# S32K344 register map
Vendor: NXP Semiconductors; File version: 1.9
CPU: CM7 r0p1, little endian, MPU, FPU, VTOR, 4 interrupt priority bits
Registers are 32-bit, read-write, reset 0x0 unless marked. A register's access mark holds for its fields unless they carry their own. Offsets are from the block's base; [hi:lo] are bit positions; {n}, {i} and the like mark numbered series; 'fields as' and 'values as' point back to an identical list.

## DCM_GPR
Base 0x402AC000; alternate view of DCM
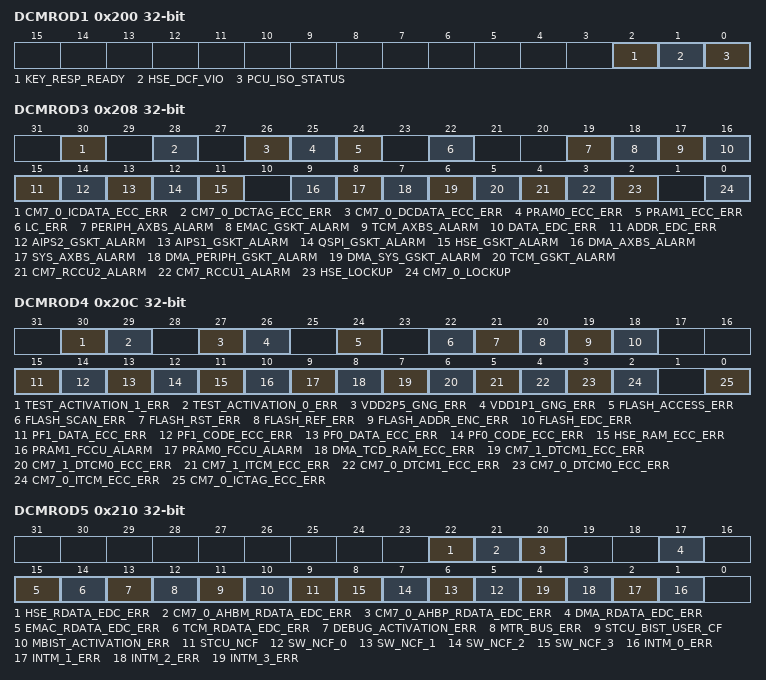
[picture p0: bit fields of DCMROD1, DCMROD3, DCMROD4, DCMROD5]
0x200 DCMROD1 write-1-clears — Read Only GPR On Destructive Reset Register
  [2] KEY_RESP_READY write-1-clears — Key Response Ready
    0=Key response is not ready; 1=Key response is ready
  [1] HSE_DCF_VIO write-1-clears — DCF violation from HSE
    0=No violation from HSE DCF records while decoding; 1=Violation from HSE DCF records while decoding
  [0] PCU_ISO_STATUS write-1-clears — PCU Input Isolation status on previous standby entry
    0=Input isolation did not get enabled in the previous standby entry; 1=Input isolation enabled in the previous standby entry
0x208 DCMROD3 write-1-clears — Read Only GPR On Destructive Reset Register
  [30] CM7_0_ICDATA_ECC_ERR write-1-clears — Multi bit ECC error from CM7_0 ICache data memory
    0=CM7_1 core not in lockup state; 1=CM7_1 core in lockup state
  [28] CM7_0_DCTAG_ECC_ERR write-1-clears — Multi bit ECC error from CM7_0 DCache tag memory. Read this bit to identify the reason of fault in case of FCCU NCF 2.
    0=No multi-bit ECC error; 1=Multi-bit ECC error
  [26] CM7_0_DCDATA_ECC_ERR write-1-clears — Multi bit ECC error from CM7_0 DCache data memory
    0=No multi-bit ECC error; 1=Multi-bit ECC error
  [25] PRAM0_ECC_ERR write-1-clears — Multi bit ECC error from SRAM0
    0=No multi-bit ECC error; 1=Multi-bit ECC error
  [24] PRAM1_ECC_ERR write-1-clears — Multi bit ECC error from SRAM1
    0=No multi-bit ECC error; 1=Multi-bit ECC error
  [22] LC_ERR write-1-clears — Error in Lifecycle Scanning. Read this bit to identify the reason of fault in case of FCCU NCF 3.
    0=No error while lifecycle scanning; 1=Error while lifecycle scanning
  [19] PERIPH_AXBS_ALARM write-1-clears — PERIPH AXBS_Lite Safety Alarm Status. Read this bit to identify the reason of fault in case of FCCU NCF 1.
    0=No safety alarm indicated by Periph AXBS_Lite; 1=Safety alarm indicated by Periph AXBS_Lite
  [18] EMAC_GSKT_ALARM write-1-clears — EMAC IAHB Gasket Alarm Status. Read this bit to identify the reason of fault in case of FCCU NCF 1.
    0=No alarm indicated by EMAC IAHB gasket; 1=Alarm indicated by EMAC IAHB gasket
  [17] TCM_AXBS_ALARM write-1-clears — TCM AHB Splitter Safety Alarm Status. Read this bit to identify the reason of fault in case of FCCU NCF 1.
    0=No safety alarm indicated by TCM AHB splitter; 1=Safety alarm indicated by TCM AHB splitter
  [16] DATA_EDC_ERR write-1-clears — Status of integrity error on data for safety
    0=No integrity error on data; 1=Data integrity error
  [15] ADDR_EDC_ERR write-1-clears — Status of integrity error on address for safety
    0=No integrity error on address; 1=Address integrity error
  [14] AIPS2_GSKT_ALARM write-1-clears — AIPS2 IAHB Gasket Alarm Status. Read this bit to identify the reason of fault in case of FCCU NCF 1.
    0=No alarm indicated by AIPS2 IAHB gasket; 1=Alarm indicated by AIPS2 IAHB gasket
  [13] AIPS1_GSKT_ALARM write-1-clears — AIPS1 IAHB Gasket Alarm Status. Read this bit to identify the reason of fault in case of FCCU NCF 1.
    0=No alarm indicated by AIPS1 IAHB gasket; 1=Alarm indicated by AIPS1 IAHB gasket
  [12] QSPI_GSKT_ALARM write-1-clears — QSPI IAHB Gasket Alarm Status. Read this bit to identify the reason of fault in case of FCCU NCF 1.
    0=No alarm indicated by QSPI IAHB gasket; 1=Alarm indicated by QSPI IAHB gasket
  [11] HSE_GSKT_ALARM write-1-clears — HSE IAHB Gasket Alarm Status. Read this bit to identify the reason of fault in case of FCCU NCF 1.
    0=No alarm indicated by HSE IAHB gasket; 1=Alarm indicated by HSE IAHB gasket
  [9] DMA_AXBS_ALARM write-1-clears — DMA AXBS_Lite Safety Alarm Status. Read this bit to identify the reason of fault in case of FCCU NCF 1.
    0=No safety alarm indicated by DMA AXBS_Lite; 1=Safety alarm indicated by DMA AXBS_Lite
  [8] SYS_AXBS_ALARM write-1-clears — System AXBS Safety Alarm Status. Read this bit to identify the reason of fault in case of FCCU NCF 1.
    0=No safety alarm indicated by system AXBS; 1=Safety alarm indicated by system AXBS
  [7] DMA_PERIPH_GSKT_ALARM write-1-clears — Status of IAHB gasket safety alarm from DMA periph AXBS IAHB gasket
    0=No safety alarm reported from DMA-periph AXBS IAHB gasket; 1=Safety alarm indicated by DMA-periph AXBS IAHB gasket
  [6] DMA_SYS_GSKT_ALARM write-1-clears — Status of IAHB gasket safety alarm from DMA system AXBS IHAB gasket
    0=No safety alarm reported from DMA-system AXBS IAHB gasket; 1=Safety alarm indicated by DMA-system AXBS IAHB gasket
  [5] TCM_GSKT_ALARM write-1-clears — TCM IAHB Gasket Monitor Alarm Status. Read this bit to identify the reason of fault in case of FCCU NCF 1.
    0=No alarm reported from TCM IAHB gasket; 1=Monitor alarm reported from TCM IAHB gasket
  [4] CM7_RCCU2_ALARM write-1-clears — Cortex M7 Cores Redundant Lockstep Error Status. Read this bit to identify the reason of fault in case of FCCU NCF 0.
    0=No lockstep alarm reported by redundant RCCU; 1=Lockstep alarm reported by redundant RCCU
  [3] CM7_RCCU1_ALARM write-1-clears — Cortex M7 Cores Lockstep Error Status. Read this bit to identify the reason of fault in case of FCCU NCF 0.
    0=No lockstep alarm reported by RCCU; 1=Lockstep alarm reported by RCCU
  [2] HSE_LOCKUP write-1-clears — HSE Core Lockup Status. Read this bit to identify the reason of fault in case of FCCU NCF 0.
    0=HSE core not in lockup state; 1=HSE core in lockup state
  [0] CM7_0_LOCKUP write-1-clears — CM7_0 Core Lockup Status. Read this bit to identify the reason of fault in case of FCCU NCF 0.
    0=CM7_0 core not in lockup state; 1=CM7_0 core in lockup state
0x20C DCMROD4 write-1-clears — Read Only GPR On Destructive Reset Register
  [30] TEST_ACTIVATION_1_ERR write-1-clears — Accidental Partial Test Activation. Read this bit to identify the reason of fault in case of FCCU NCF 5.
    0=No partial test activated accidentally; 1=Partial test activated accidentally
  [29] TEST_ACTIVATION_0_ERR write-1-clears — Accidental Partial Test Activation. Read this bit to identify the reason of fault in case of FCCU NCF 5.
    values as TEST_ACTIVATION_1_ERR
  [27] VDD2P5_GNG_ERR write-1-clears — Go/no-go for VDD_HV_FLA (double bond) going to FXOSC and PLL
    0=Go indication referring to the supply being clean; 1=No-go indication referring to the supply being unclean and a fault in double bond connection or its routing within the chip
  [26] VDD1P1_GNG_ERR write-1-clears — Go/no-go indicator for VDD1PD1 (double bond) supply going to PLL
    values as VDD2P5_GNG_ERR
  [24] FLASH_ACCESS_ERR write-1-clears — Transaction Monitor Mismatch Error From Flash Controller
    0=No transaction monitor mismatch error from flash controller; 1=Transaction monitor mismatch error from flash controller
  [22] FLASH_SCAN_ERR write-1-clears — Error while DCM flash scanning process due to invalid data
    0=No error while DCM flash scanning; 1=Error while DCM flash scanning
  [21] FLASH_RST_ERR write-1-clears — Flash Reset Error Status
    0=No flash reset error indicated; 1=Flash reset error indicated
  [20] FLASH_REF_ERR write-1-clears — Flash reference current loss or read voltage error while prevoius read(s)
    0=No reference current loss or read voltage error while previous reads(s); 1=Reference current loss or read voltage error while previous read(s)
  [19] FLASH_ADDR_ENC_ERR write-1-clears — Flash Address Encode Error
    0=No address encode error in flash; 1=Address enocde error in flash
  [18] FLASH_EDC_ERR write-1-clears — Status of flash ECC correction error through EDC reported by FMU
    0=No EDC after ECC error reported in flash; 1=EDC after ECC error reported in flash
  [15] PF1_DATA_ECC_ERR write-1-clears — Flash1 Data ECC Uncorrectable Error
    0=No uncorrectable error reported in flash controller port 1 data memory by FMU; 1=Uncorrectable error reported in flash controller port 1 data memory by FMU
  [14] PF1_CODE_ECC_ERR write-1-clears — Flash1 Code ECC Uncorrectable Error
    0=No uncorrectable error reported in flash controller port 1 code memory by FMU; 1=Uncorrectable error reported in flash controller port 1 code memory by FMU
  [13] PF0_DATA_ECC_ERR write-1-clears — Flash0 Data ECC Uncorrectable Error
    0=No uncorrectable error reported in flash controller port 0 data memory by FMU; 1=Uncorrectable error reported in flash controller port 0 data memory by FMU
  [12] PF0_CODE_ECC_ERR write-1-clears — Flash0 Code ECC Uncorrectable Error
    0=No uncorrectable error reported in flash controller port 0 code memory by FMU; 1=Uncorrectable error reported in flash controller port 0 code memory by FMU
  [11] HSE_RAM_ECC_ERR write-1-clears — HSE RAM Uncorrectable ECC Status. Read this bit to identify the reason of fault in case of FCCU NCF 2.
    0=No uncorrectable ECC reported by HSE RAM; 1=Uncorrectable ECC reported by HSE RAM
  [10] PRAM1_FCCU_ALARM write-1-clears — Status of PRAM1 safety alarm
    0=No safety alarm indicated by PRAM1; 1=Safety alarm indicated by PRAM1
  [9] PRAM0_FCCU_ALARM write-1-clears — Status of PRAM0 safety alarm
    0=No safety alarm indicated by PRAM0; 1=Safety alarm indicated by PRAM0
  [8] DMA_TCD_RAM_ECC_ERR write-1-clears — Uncorrectable ECC error reported from DMA_TCD memory
    0=No uncorrectable ECC error detected; 1=Uncorrectable ECC error detected
  [7] CM7_1_DTCM1_ECC_ERR write-1-clears — Uncorrectable ECC error reported from CM7_1 Data TCM memory block 1
    values as DMA_TCD_RAM_ECC_ERR
  [6] CM7_1_DTCM0_ECC_ERR write-1-clears — Uncorrectable ECC error reported from CM7_1 Data TCM memory block 0
    values as DMA_TCD_RAM_ECC_ERR
  [5] CM7_1_ITCM_ECC_ERR write-1-clears — Uncorrectable ECC error reported from CM7_1 Instruction TCM memory
    values as DMA_TCD_RAM_ECC_ERR
  [4] CM7_0_DTCM1_ECC_ERR write-1-clears — Uncorrectable ECC error reported from CM7_0 Data TCM memory block 1
    values as DMA_TCD_RAM_ECC_ERR
  [3] CM7_0_DTCM0_ECC_ERR write-1-clears — Uncorrectable ECC error reported from CM7_0 Data TCM memory block 0
    values as DMA_TCD_RAM_ECC_ERR
  [2] CM7_0_ITCM_ECC_ERR write-1-clears — Uncorrectable ECC error reported from CM7_0 Instruction TCM memory
    values as DMA_TCD_RAM_ECC_ERR
  [0] CM7_0_ICTAG_ECC_ERR write-1-clears — Multi bit ECC error from CM7_0 ICache tag memory
    0=No multi-bit ECC error; 1=Multi-bit ECC error
0x210 DCMROD5 write-1-clears — Read Only GPR On Destructive Reset Register
  [22] HSE_RDATA_EDC_ERR write-1-clears — Integrity (EDC) error on HSE read data for safety
    0=No integrity error reported on HSE read data; 1=Integrity error reported on HSE read data
  [21] CM7_0_AHBM_RDATA_EDC_ERR write-1-clears — Integrity error on CM7_0 main read data for safety
    0=No integrity error reported on CM7_0 main read data; 1=Integrity error reported on CM7_0 main read data
  [20] CM7_0_AHBP_RDATA_EDC_ERR write-1-clears — Integrity error on CM7_0 peripheral read data for safety
    0=No integrity error reported on CM7_0 peripheral read data; 1=Integrity error reported on CM7_0 peripheral read data
  [17] DMA_RDATA_EDC_ERR write-1-clears — Integrity(EDC) error on eDMA read data for safety
    0=No integrity error reported on eDMA read data; 1=Integrity error reported on eDMA read data
  [15] EMAC_RDATA_EDC_ERR write-1-clears — Integrity(EDC) error on EMAC read data for safety
    0=No integrity error reported on EMAC read data; 1=Integrity error reported on EMAC read data
  [14] TCM_RDATA_EDC_ERR write-1-clears — Integrity(EDC) error on TCM read data for safety
    0=No integrity error reported on TCM read data; 1=Integrity error reported on TCM read data
  [13] DEBUG_ACTIVATION_ERR write-1-clears — Monitoring of unintended debug activation
    0=Unintended debug not activated; 1=Unintended debug activated
  [12] MTR_BUS_ERR write-1-clears — Fault reported due to illegal access on MTR
    0=No transfer error indicated from MTR; 1=Transfer error indicated from MTR
  [11] STCU_BIST_USER_CF write-1-clears — L/M BIST enabled accidentally
    0=No accidental L/M BIST enabled; 1=Accidental L/M BIST enabled
  [10] MBIST_ACTIVATION_ERR write-1-clears — Indicates an accidental backdoor access on memories
    0=No accidental backdoor enabled on memories; 1=Accidental backdoor enabled on memories
  [9] STCU_NCF write-1-clears — STCU non-critical fault, that is, BIST result error
    0=STCU non-critical fault not reported; 1=STCU non-critical fault reported
  [n+5] SW_NCF_{n} write-1-clears (n=0..3) — Software NCF{n} Status
    0=Software NCF{n}, DCMRWF1[FCCU_SW_NCF{n}] not enabled by software; 1=Software NCF{n}, DCMRWF1[FCCU_SW_NCF{n}] enabled by software
  [n+1] INTM_{n}_ERR write-1-clears (n=0..3) — Interrupt monitor{n} error reported by INTM
    0=No error reported by interrupt monitor {n}; 1=Error reported by interrupt monitor {n}
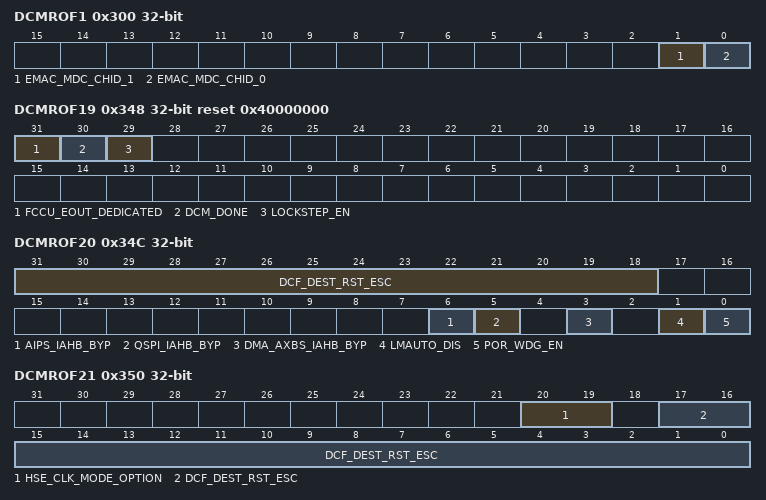
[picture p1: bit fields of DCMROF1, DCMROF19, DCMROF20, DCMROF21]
0x300 DCMROF1 write-1-clears — Read Only GPR On Functional Reset Register
  [1] EMAC_MDC_CHID_1 write-1-clears — EMAC DMA Channel ID1 Status
    0=Channel ID1 is not the current transfer channel ID; 1=Channel ID1 is the current transfer channel ID
  [0] EMAC_MDC_CHID_0 write-1-clears — EMAC DMA Channel ID0 Status
    0=Channel ID0 is not the current transfer channel ID; 1=Channel ID0 is the current transfer channel ID
{0x2FC+4i} DCMROF{i} write-1-clears (i=2..17) — Read Only GPR On Functional Reset Register
  [31:0] DCF_SDID{i-2} write-1-clears — Configuration bits of DCF client SDID {i-2}.
0x348 DCMROF19 ro reset 0x40000000 — Read Only GPR On Functional Reset Register
  [31] FCCU_EOUT_DEDICATED
    0=FCCU_EOUT pins on GPIO2 and GPIO3 acts as general purpose pins supporting all functions; 1=FCCU_EOUT pins on GPIO2 and GPIO3 acts as dedicated EOUT pins
  [30] DCM_DONE
    0=Flash scanning by DCM not complete; 1=Flash scanning completed by DCM
  [29] LOCKSTEP_EN — Lockstep Enable
    0=The chip current operation mode is decoupled operation of CM7_0 and CM7_1; 1=The chip current operation mode is lockstep operation of CM7_0 and CM7_1
0x34C DCMROF20 ro (reset mask 0x3FF94) — Read Only GPR On Functional Reset Register
  [31:18] DCF_DEST_RST_ESC — This register indicates the information of chip destructive reset escalation support for destructive reset sources as configured in DCF record, DEST_RST_ESC[13:0]
    0=Destructive Reset Escalation disabled; 1=Destructive Reset Escalation enabled
  [6] AIPS_IAHB_BYP — Status of AIPS1/2 IAHB gasket as configured in DCF record, UTEST_MISC[AIPS_IAHB_BYP].
    0=Register wall enabled; 1=Register wall bypassed
  [5] QSPI_IAHB_BYP — Status of QSPI IAHB gasket as configured in DCF record, UTEST_MISC[QSPI_IAHB_BYP].
    0=Register wall enabled; 1=Register wall bypassed
  [3] DMA_AXBS_IAHB_BYP — Status of DMA AXBS IAHB gasket as configured in DCF record, UTEST_MISC[DMA_AXBS_IAHB_BYP].
    0=Register wall enabled; 1=Register wall bypassed
  [1] LMAUTO_DIS — PMC last mile automatic croosover from boot regulationfeature support.
    0=Last mile auto crossover feautre is supported for the chip; 1=Last mile auto crossover feautre is not supported for the chip
  [0] POR_WDG_EN — Indicates the status of POR_WDG as configured in DCF record, UTEST_MISC[POR_WDG_EN].
    0=POR Watchdog Disabled; 1=POR Watchdog Enabled (default)
0x350 DCMROF21 ro — Read Only GPR On Functional Reset Register
  [20:19] HSE_CLK_MODE_OPTION — HSE Clock Mode Option
    0=Applicable for clocking option A. Ratio of 1:2 in between HSE IPS interface clock (AIPS_SLOW_CLK) and HSE module clock (HSE_CLK), HSE_IAHB gasket enabled.; 1=Applicable for clocking option C, D, E, E2, and F. Ratio of 1:2 in between HSE IPS interface clock (AIPS_SLOW_CLK) and HSE module clock (HSE_CLK), HSE_IAHB gasket bypass.; 2=10b and 11b both are applicable for clocking option B in same way. Ratio of 1:4 in between HSE IPS interface clock (AIPS_SLOW_CLK) and HSE module clock (HSE_CLK), HSE_IAHB gasket enabled.; 3=10b and 11b both are applicable for clocking option B in same way. Ratio of 1:4 in between HSE IPS interface clock (AIPS_SLOW_CLK) and HSE module clock (HSE_CLK), HSE_IAHB gasket enabled.
  [17:0] DCF_DEST_RST_ESC — This register indicates the information of chip destructive reset escalation support for destructive reset sources as configured in DCF record, DEST_RST_ESC[31:14]
    values as DCMROF20.DCF_DEST_RST_ESC
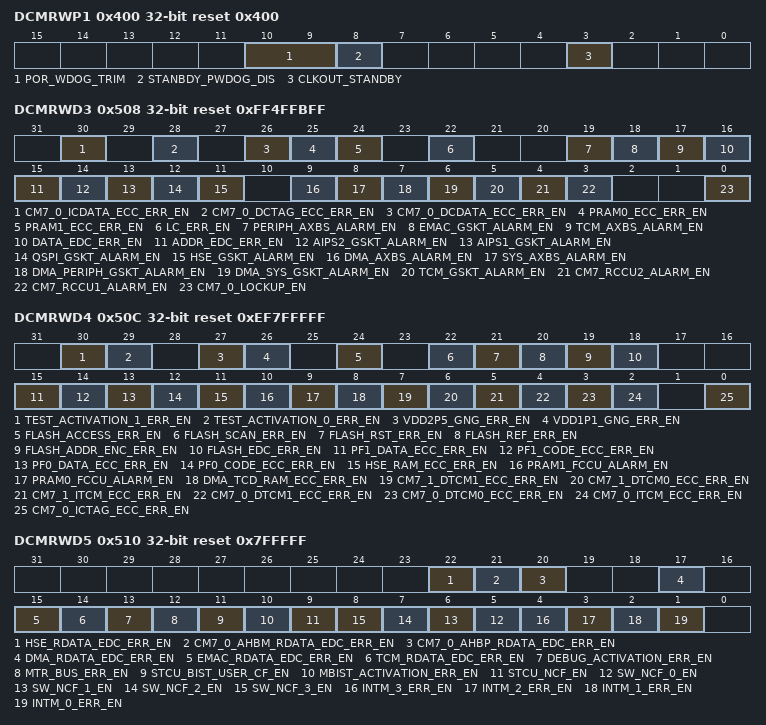
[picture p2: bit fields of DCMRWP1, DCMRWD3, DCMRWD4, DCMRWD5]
0x400 DCMRWP1 reset 0x400 — Read Write GPR On Power On Reset Register
  [10:9] POR_WDOG_TRIM — Trims for POR WDG timeout value.
  [8] STANBDY_PWDOG_DIS — Disables the standby entry and exit monitoring window of the POR WDOG.
    0=Enabled; 1=Disabled
  [3] CLKOUT_STANDBY — Clockout standby expose over functional and destructive reset.
    0=The CLKOUT_STANDBY function is not available while functional or destructive reset on PTA12; 1=The CLKOUT_STANDBY function is available while functional or destructive reset on PTA12
0x408 DCMRWP3 — Read Write GPR On Power On Reset Register
  [9] DEST_RST9_AS_IPI — Configures a destructive reset to interrupt.
    0=Destructive reset; 1=PLL LOL interrupt
0x504 DCMRWD2 — Read Write GPR On Destructive Reset Register
  [7] EOUT_STAT_DUR_STEST — Controls the EOUT state during selftest.
    0=EOUT state will change to high Z post selftest when device is under reset; 1=EOUT state will remain in FAULT state until this bit is cleared
0x508 DCMRWD3 reset 0xFF4FFBFF — Read Write GPR On Destructive Reset Register
  [30] CM7_0_ICDATA_ECC_ERR_EN — Enable bit for enabling the fault monitoring at FCCU NCF 2 for the fault: Multi bit ECC error from CM7_0 ICache data memory
    0=No multi-bit ECC error; 1=Multi-bit ECC error
  [28] CM7_0_DCTAG_ECC_ERR_EN — Enable bit for enabling the fault monitoring at FCCU NCF 2 for the fault: Multi bit ECC error from CM7_0 DCache tag memory
    0=No multi-bit ECC error; 1=Multi-bit ECC error
  [26] CM7_0_DCDATA_ECC_ERR_EN — Enable bit for enabling the fault monitoring at FCCU NCF 2 for the fault: Multi bit ECC error from CM7_0 DCache data memory
    0=No multi-bit ECC error; 1=Multi-bit ECC error
  [25] PRAM0_ECC_ERR_EN — Enable bit for enabling the fault monitoring at FCCU NCF 2 for the fault: Multi bit ECC error from SRAM0
    0=No multi-bit ECC error; 1=Multi-bit ECC error
  [24] PRAM1_ECC_ERR_EN — Enable bit for enabling the fault monitoring at FCCU NCF 2 for the fault: Multi bit ECC error from SRAM1
    0=No multi-bit ECC error; 1=Multi-bit ECC error
  [22] LC_ERR_EN — Enable bit for enabling the fault monitoring at FCCU NCF 3 for the fault: Error in lifecycle scanning
    values as DCMROD3.LC_ERR
  [19] PERIPH_AXBS_ALARM_EN — Enable bit for enabling the fault monitoring at FCCU NCF 1 for the fault: PERIPH AXBS_Lite safety alarm
    values as DCMROD3.PERIPH_AXBS_ALARM
  [18] EMAC_GSKT_ALARM_EN — Enable bit for enabling the fault monitoring at FCCU NCF 1 for the fault: EMAC IAHB gasket alarm.
    values as DCMROD3.EMAC_GSKT_ALARM
  [17] TCM_AXBS_ALARM_EN — Enable bit for enabling the fault monitoring at FCCU NCF 1 for the fault: TCM AHB splitter safety alarm
    values as DCMROD3.TCM_AXBS_ALARM
  [16] DATA_EDC_ERR_EN — Enable bit for enabling the fault monitoring at FCCU NCF 1 for the fault: integrity error on data for safety
    0=No integrity error on data; 1=Data integrity error
  [15] ADDR_EDC_ERR_EN — Enable bit for enabling the fault monitoring at FCCU NCF 1 for the fault: integrity error on address for safety
    0=No integrity error on address; 1=Address integrity error
  [14] AIPS2_GSKT_ALARM_EN — Enable bit for enabling the fault monitoring at FCCU NCF 1 for the fault: AIPS2 IAHB gasket alarm.
    values as DCMROD3.AIPS2_GSKT_ALARM
  [13] AIPS1_GSKT_ALARM_EN — Enable bit for enabling the fault monitoring at FCCU NCF 1 for the fault: AIPS1 IAHB gasket alarm.
    values as DCMROD3.AIPS1_GSKT_ALARM
  [12] QSPI_GSKT_ALARM_EN — Enable bit for enabling the fault monitoring at FCCU NCF 1 for the fault: QSPI IAHB gasket alarm.
    values as DCMROD3.QSPI_GSKT_ALARM
  [11] HSE_GSKT_ALARM_EN — Enable bit for enabling the fault monitoring at FCCU NCF 1 for the fault: HSE IAHB gasket alarm.
    values as DCMROD3.HSE_GSKT_ALARM
  [9] DMA_AXBS_ALARM_EN — Enable bit for enabling the fault monitoring at FCCU NCF 1 for the fault: DMA AXBS_Lite safety alarm
    values as DCMROD3.DMA_AXBS_ALARM
  [8] SYS_AXBS_ALARM_EN — Enable bit for enabling the fault monitoring at FCCU NCF 1 for the fault: system AXBS safety alarm.
    values as DCMROD3.SYS_AXBS_ALARM
  [7] DMA_PERIPH_GSKT_ALARM_EN — Enable bit for enabling the fault monitoring at FCCU NCF 1 for the fault: IAHB gasket safety alarm from DMA periph AXBS IAHB gasket
    values as DCMROD3.DMA_PERIPH_GSKT_ALARM
  [6] DMA_SYS_GSKT_ALARM_EN — Enable bit for enabling the fault monitoring at FCCU NCF 1 for the fault: IAHB gasket safety alarm from DMA system AXBS IHAB gasket
    values as DCMROD3.DMA_SYS_GSKT_ALARM
  [5] TCM_GSKT_ALARM_EN — Enable bit for enabling the fault monitoring at FCCU NCF 1 for the fault: TCM IAHB Gasket monitor alarm
    values as DCMROD3.TCM_GSKT_ALARM
  [4] CM7_RCCU2_ALARM_EN — Enable bit for enabling the fault monitoring at FCCU NCF 0 for the fault: Cortex M7 cores redundant lockstep error
    values as DCMROD3.CM7_RCCU2_ALARM
  [3] CM7_RCCU1_ALARM_EN — Enable bit for enabling the fault monitoring at FCCU NCF 0 for the fault: Cortex M7 cores lockstep error
    values as DCMROD3.CM7_RCCU1_ALARM
  [0] CM7_0_LOCKUP_EN — Enable bit for enabling the fault monitoring at FCCU NCF 0 for the fault: CM7_0 core lockup.
    values as DCMROD3.CM7_0_LOCKUP
0x50C DCMRWD4 reset 0xEF7FFFFF — Read Write GPR On Destructive Reset Register
  [30] TEST_ACTIVATION_1_ERR_EN — Enable bit for enabling the fault monitoring at FCCU NCF 5 for the fault: Accidental partial test activation
    values as DCMROD4.TEST_ACTIVATION_1_ERR
  [29] TEST_ACTIVATION_0_ERR_EN — Enable bit for enabling the fault monitoring at FCCU NCF 5 for the fault: Accidental partial test activation
    values as DCMROD4.TEST_ACTIVATION_1_ERR
  [27] VDD2P5_GNG_ERR_EN — Enable bit for enabling the fault monitoring at FCCU NCF 4 for the fault: Go/Nogo for VDD_HV_FLA (double bond) going to FXOSC and PLL
    0=Go indication referring to the supply being clean; 1=No go indication referring to the supply being unclean and a fault in double bond connection or its routing within the chip
  [26] VDD1P1_GNG_ERR_EN — Enable bit for enabling the fault monitoring at FCCU NCF 4 for the fault: Go/Nogo indicator for VDD1PD1 (double bond) supply going to PLL
    values as VDD2P5_GNG_ERR_EN
  [24] FLASH_ACCESS_ERR_EN — Enable bit for enabling the fault monitoring at FCCU NCF 3 for the fault: Transaction monitor mismatch error from flash controller
    values as DCMROD4.FLASH_ACCESS_ERR
  [22] FLASH_SCAN_ERR_EN — Enable bit for enabling the fault monitoring at FCCU NCF 3 for the fault: Error while DCM flash scanning process due to invalid data
    values as DCMROD4.FLASH_SCAN_ERR
  [21] FLASH_RST_ERR_EN — Enable bit for enabling the fault monitoring at FCCU NCF 3 for the fault: Flash reset error
    values as DCMROD4.FLASH_RST_ERR
  [20] FLASH_REF_ERR_EN — Enable bit for enabling the fault monitoring at FCCU NCF 3 for the fault: Flash reference current loss or read voltage error while prevoius read(s)
    values as DCMROD4.FLASH_REF_ERR
  [19] FLASH_ADDR_ENC_ERR_EN — Enable bit for enabling the fault monitoring at FCCU NCF 3 for the fault: Flash address encode error
    0=No address encode error in flash; 1=Address encode error in flash
  [18] FLASH_EDC_ERR_EN — Enable bit for enabling the fault monitoring at FCCU NCF 3 for the fault: Flash ECC correction error through EDC reported by FMU
    values as DCMROD4.FLASH_EDC_ERR
  [15] PF1_DATA_ECC_ERR_EN — Enable bit for enabling the fault monitoring at FCCU NCF 3 for the fault: Flash1 data ECC uncorrectable error
    values as DCMROD4.PF1_DATA_ECC_ERR
  [14] PF1_CODE_ECC_ERR_EN — Enable bit for enabling the fault monitoring at FCCU NCF 3 for the fault: Flash1 code ECC uncorrectable error
    values as DCMROD4.PF1_CODE_ECC_ERR
  [13] PF0_DATA_ECC_ERR_EN — Enable bit for enabling the fault monitoring at FCCU NCF 3 for the fault: Flash0 data ECC uncorrectable error
    values as DCMROD4.PF0_DATA_ECC_ERR
  [12] PF0_CODE_ECC_ERR_EN — Enable bit for enabling the fault monitoring at FCCU NCF 3 for the fault: Flash0 code ECC uncorrectable error
    values as DCMROD4.PF0_CODE_ECC_ERR
  [11] HSE_RAM_ECC_ERR_EN — Enable bit for enabling the fault monitoring at FCCU NCF 2 for the fault: HSE RAM Uncorrectable ECC
    values as DCMROD4.HSE_RAM_ECC_ERR
  [10] PRAM1_FCCU_ALARM_EN — Enable bit for enabling the fault monitoring at FCCU NCF 2 for the fault: PRAM1 safety alarm
    values as DCMROD4.PRAM1_FCCU_ALARM
  [9] PRAM0_FCCU_ALARM_EN — Enable bit for enabling the fault monitoring at FCCU NCF 2 for the fault: PRAM0 safety alarm
    values as DCMROD4.PRAM0_FCCU_ALARM
  [8] DMA_TCD_RAM_ECC_ERR_EN — Enable bit for enabling the fault monitoring at FCCU NCF 2 for the fault: Uncorrectable ECC error reported from DMA_TCD memory
    0=Uncorrectable ECC error detection at FCCU not enabled; 1=Uncorrectable ECC error detection enabled at FCCU
  [7] CM7_1_DTCM1_ECC_ERR_EN — Enable bit for enabling the fault monitoring at FCCU NCF 2 for the fault: Uncorrectable ECC error from CM7_1 Data TCM memory block 1
    values as DMA_TCD_RAM_ECC_ERR_EN
  [6] CM7_1_DTCM0_ECC_ERR_EN — Enable bit for enabling the fault monitoring at FCCU NCF 2 for the fault: Uncorrectable ECC error from CM7_1 Data TCM memory block 0
    values as DMA_TCD_RAM_ECC_ERR_EN
  [5] CM7_1_ITCM_ECC_ERR_EN — Enable bit for enabling the fault monitoring at FCCU NCF 2 for the fault: Uncorrectable ECC error from CM7_1 Instruction TCM memory
    values as DMA_TCD_RAM_ECC_ERR_EN
  [4] CM7_0_DTCM1_ECC_ERR_EN — Enable bit for enabling the fault monitoring at FCCU NCF 2 for the fault: Uncorrectable ECC error from CM7_0 Data TCM memory block 1
    values as DMA_TCD_RAM_ECC_ERR_EN
  [3] CM7_0_DTCM0_ECC_ERR_EN — Enable bit for enabling the fault monitoring at FCCU NCF 2 for the fault: Uncorrectable ECC error from CM7_0 Data TCM memory block 0
    values as DMA_TCD_RAM_ECC_ERR_EN
  [2] CM7_0_ITCM_ECC_ERR_EN — Enable bit for enabling the fault monitoring at FCCU NCF 2 for the fault: Uncorrectable ECC error from CM7_0 Instruction TCM memory
    values as DMA_TCD_RAM_ECC_ERR_EN
  [0] CM7_0_ICTAG_ECC_ERR_EN — Enable bit for enabling the fault monitoring at FCCU NCF 2 for the fault: Multi bit ECC error from CM7_0 ICache tag memory
    0=No multi-bit ECC error; 1=Multi-bit ECC error
0x510 DCMRWD5 reset 0x7FFFFF — Read Write GPR On Destructive Reset Register
  [22] HSE_RDATA_EDC_ERR_EN — Enable bit for enabling the fault monitoring at FCCU NCF 1 for the fault: Integrity (EDC) error on HSE read data for safety
    values as DCMROD5.HSE_RDATA_EDC_ERR
  [21] CM7_0_AHBM_RDATA_EDC_ERR_EN — Enable bit for enabling the fault monitoring at FCCU NCF 1 for the fault: Integrity error on CM7_0 main read data for safety
    values as DCMROD5.CM7_0_AHBM_RDATA_EDC_ERR
  [20] CM7_0_AHBP_RDATA_EDC_ERR_EN — Enable bit for enabling the fault monitoring at FCCU NCF 1 for the fault: Integrity error on CM7_0 peripheral read data for safety
    values as DCMROD5.CM7_0_AHBP_RDATA_EDC_ERR
  [17] DMA_RDATA_EDC_ERR_EN — Enable bit for enabling the fault monitoring at FCCU NCF 1 for the fault: Integrity(EDC) error on eDMA read data for safety
    values as DCMROD5.DMA_RDATA_EDC_ERR
  [15] EMAC_RDATA_EDC_ERR_EN — Enable bit for enabling the fault monitoring at FCCU NCF 1 for the fault: Integrity(EDC) error on EMAC read data for safety
    values as DCMROD5.EMAC_RDATA_EDC_ERR
  [14] TCM_RDATA_EDC_ERR_EN — Enable bit for enabling the fault monitoring at FCCU NCF 1 for the fault: Integrity(EDC) error on TCM read data for safety
    values as DCMROD5.TCM_RDATA_EDC_ERR
  [13] DEBUG_ACTIVATION_ERR_EN — Enable bit for enabling the fault monitoring at FCCU NCF 5 for the fault: Monitoring of unintended debug activation
    values as DCMROD5.DEBUG_ACTIVATION_ERR
  [12] MTR_BUS_ERR_EN — Enable bit for enabling the fault monitoring at FCCU NCF 5 for the fault: Fault reported due to illegal access on MTR
    values as DCMROD5.MTR_BUS_ERR
  [11] STCU_BIST_USER_CF_EN — Enable bit for enabling the fault monitoring at FCCU NCF 5 for the fault: L/M BIST enabled accidentally
    values as DCMROD5.STCU_BIST_USER_CF
  [10] MBIST_ACTIVATION_ERR_EN — Enable bit for enabling the fault monitoring at FCCU NCF 5 for the fault: Indicates an accidental backdoor access on memories
    values as DCMROD5.MBIST_ACTIVATION_ERR
  [9] STCU_NCF_EN — Enable bit for enabling the fault monitoring at FCCU NCF 5 for the fault: STCU non-critical fault, that is, BIST result error
    values as DCMROD5.STCU_NCF
  [n+5] SW_NCF_{n}_EN (n=0..3) — Enable bit for enabling the fault monitoring at FCCU NCF 7 for the fault: Software NCF{n}
    values as DCMROD5.SW_NCF_0
  [4] INTM_3_ERR_EN — Enable bit for enabling the fault monitoring at FCCU NCF 6 for the fault: Interrupt monitor3 error reported by error reported by INTM
    0=No error reported by interrupt monitor 3; 1=Error reported by interrupt monitor 3
  [3] INTM_2_ERR_EN — Enable bit for enabling the fault monitoring at FCCU NCF 6 for the fault: Interrupt monitor2 error reported by error reported by INTM
    0=No error reported by interrupt monitor 2; 1=Error reported by interrupt monitor 2
  [2] INTM_1_ERR_EN — Enable bit for enabling the fault monitoring at FCCU NCF 6 for the fault: Interrupt monitor1 error reported by error reported by INTM
    0=No error reported by interrupt monitor 1; 1=Error reported by interrupt monitor 1
  [1] INTM_0_ERR_EN — Enable bit for enabling the fault monitoring at FCCU NCF 6 for the fault: Interrupt monitor0 error reported by INTM
    0=No error reported by interrupt monitor 0; 1=Error reported by interrupt monitor 0
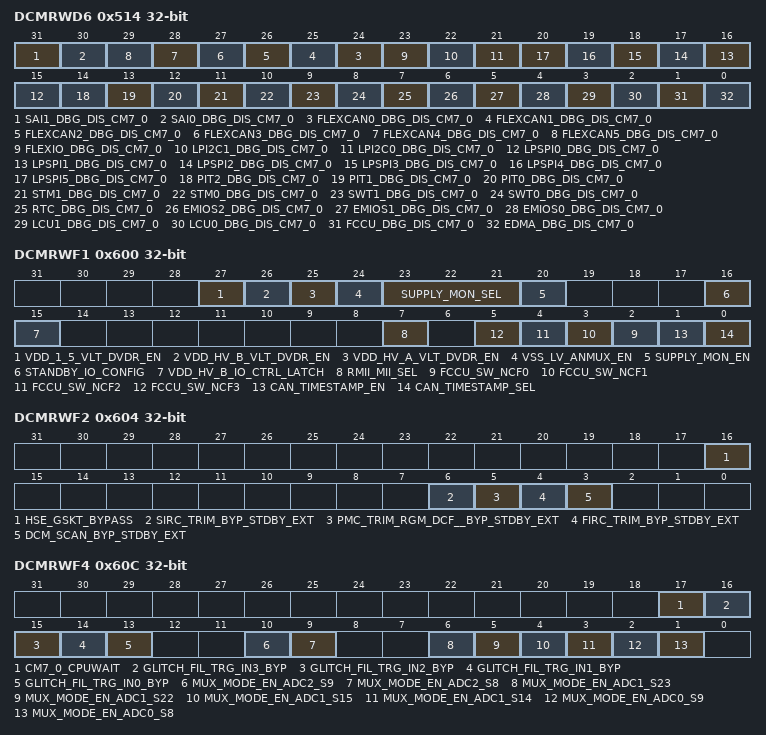
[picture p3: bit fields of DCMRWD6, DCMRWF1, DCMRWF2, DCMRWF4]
0x514 DCMRWD6 — Read Write GPR On Destructive Reset Register
  [31] SAI1_DBG_DIS_CM7_0 — SAI1 debug disable bit for CM7_0. Set this bit 1 to disable the debug of IP.
    0=SAI1 enters debug mode when CM7_0 enters debug mode; 1=SAI1 remains functional and is not impacted when CM7_0 enters debug mode
  [30] SAI0_DBG_DIS_CM7_0 — SAI0 debug disable bit for CM7_0. Set this bit 1 to disable the debug of IP.
    0=SAI0 enters debug mode when CM7_0 enters debug mode; 1=SAI0 remains functional and is not impacted when CM7_0 enters debug mode
  [n+24] FLEXCAN{n}_DBG_DIS_CM7_0 (n=0..5) — FLEXCAN{n} debug disable bit for CM7_0. Set this bit 1 to disable the debug of IP.
    0=FLEXCAN{n} enters debug mode when CM7_0 enters debug mode; 1=FLEXCAN{n} remains functional and is not impacted when CM7_0 enters debug mode
  [23] FLEXIO_DBG_DIS_CM7_0 — FLEXIO debug disable bit for CM7_0. Set this bit 1 to disable the debug of IP.
    0=FLEXIO enters debug mode when CM7_0 enters debug mode; 1=FLEXIO remains functional and is not impacted when CM7_0 enters debug mode
  [22] LPI2C1_DBG_DIS_CM7_0 — LPI2C1 debug disable bit for CM7_0. Set this bit 1 to disable the debug of IP.
    0=LPI2C1 enters debug mode when CM7_0 enters debug mode; 1=LPI2C1 remains functional and is not impacted when CM7_0 enters debug mode
  [21] LPI2C0_DBG_DIS_CM7_0 — LPI2C0 debug disable bit for CM7_0. Set this bit 1 to disable the debug of IP.
    0=LPI2C0 enters debug mode when CM7_0 enters debug mode; 1=LPI2C0 remains functional and is not impacted when CM7_0 enters debug mode
  [n+15] LPSPI{n}_DBG_DIS_CM7_0 (n=0..5) — LPSPI{n} debug disable bit for CM7_0. Set this bit 1 to disable the debug of IP.
    0=LPSPI{n} enters debug mode when CM7_0 enters debug mode; 1=LPSPI{n} remains functional and is not impacted when CM7_0 enters debug mode
  [14] PIT2_DBG_DIS_CM7_0 — PIT2 debug disable bit for CM7_0. Set this bit 1 to disable the debug of IP.
    0=PIT2 enters debug mode when CM7_0 enters debug mode; 1=PIT2 remains functional and is not impacted when CM7_0 enters debug mode
  [13] PIT1_DBG_DIS_CM7_0 — PIT1 debug disable bit for CM7_0. Set this bit 1 to disable the debug of IP.
    0=PIT1 enters debug mode when CM7_0 enters debug mode; 1=PIT1 remains functional and is not impacted when CM7_0 enters debug mode
  [12] PIT0_DBG_DIS_CM7_0 — PIT0 debug disable bit for CM7_0. Set this bit 1 to disable the debug of IP.
    0=PIT0 enters debug mode when CM7_0 enters debug mode; 1=PIT0 remains functional and is not impacted when CM7_0 enters debug mode
  [11] STM1_DBG_DIS_CM7_0 — STM1 debug disable bit for CM7_0. Set this bit 1 to disable the debug of IP.
    0=STM1 enters debug mode when CM7_0 enters debug mode; 1=STM1 remains functional and is not impacted when CM7_0 enters debug mode
  [10] STM0_DBG_DIS_CM7_0 — STM0 debug disable bit for CM7_0. Set this bit 1 to disable the debug of IP.
    0=STM0 enters debug mode when CM7_0 enters debug mode; 1=STM0 remains functional and is not impacted when CM7_0 enters debug mode
  [9] SWT1_DBG_DIS_CM7_0 — SWT1 debug disable bit for CM7_0. Set this bit 1 to disable the debug of IP.
    0=SWT0 enters debug mode when CM7_0 enters debug mode; 1=SWT0 remains functional and is not impacted when CM7_0 enters debug mode
  [8] SWT0_DBG_DIS_CM7_0 — SWT0 debug disable bit for CM7_0. Set this bit 1 to disable the debug of IP.
    values as SWT1_DBG_DIS_CM7_0
  [7] RTC_DBG_DIS_CM7_0 — RTC debug disable bit for CM7_0. Set this bit 1 to disable the debug of IP.
    0=RTC enters debug mode when CM7_0 enters debug mode; 1=RTC remains functional and is not impacted when CM7_0 enters debug mode
  [6] EMIOS2_DBG_DIS_CM7_0 — EMIOS2 debug disable bit for CM7_0. Set this bit 1 to disable the debug of IP.
    0=eMIOS2 enters debug mode when CM7_0 enters debug mode; 1=eMIOS2 remains functional and is not impacted when CM7_0 enters debug mode
  [5] EMIOS1_DBG_DIS_CM7_0 — EMIOS1 debug disable bit for CM7_0. Set this bit 1 to disable the debug of IP.
    0=eMIOS1 enters debug mode when CM7_0 enters debug mode; 1=eMIOS1 remains functional and is not impacted when CM7_0 enters debug mode
  [4] EMIOS0_DBG_DIS_CM7_0 — EMIOS0 debug disable bit for CM7_0. Set this bit 1 to disable the debug of IP.
    0=eMIOS0 enters debug mode when CM7_0 enters debug mode; 1=eMIOS0 remains functional and is not impacted when CM7_0 enters debug mode
  [3] LCU1_DBG_DIS_CM7_0 — LCU1 debug disable bit for CM7_0. Set this bit 1 to disable the debug of IP.
    0=LCU1 enters debug mode when CM7_0 enters debug mode; 1=LCU1 remains functional and is not impacted when CM7_0 enters debug mode
  [2] LCU0_DBG_DIS_CM7_0 — LCU0 debug disable bit for CM7_0. Set this bit 1 to disable the debug of IP.
    0=LCU0 enters debug mode when CM7_0 enters debug mode; 1=LCU0 remains functional and is not impacted when CM7_0 enters debug mode
  [1] FCCU_DBG_DIS_CM7_0 — FCCU debug disable bit for CM7_0. Set this bit 1 to disable the debug of IP.
    0=FCCU enters debug mode when CM7_0 enters debug mode; 1=FCCU remains functional and is not impacted when CM7_0 enters debug mode
  [0] EDMA_DBG_DIS_CM7_0 — EDMA debug disable bit for CM7_0. Set this bit 1 to disable the debug of IP.
    0=EDMA enters debug mode when CM7_0 enters debug mode; 1=EDMA remains functional and is not impacted when CM7_0 enters debug mode
{0x4FC+4i} DCMRWD{i} (i=7..9) — Read Write GPR On Destructive Reset Register
0x600 DCMRWF1 — Read Write GPR On Functional Reset Register
  [27] VDD_1_5_VLT_DVDR_EN — Enable for VDD1P5 2:1 divider for voltage measurement using supply voltage monitoring by ADC.
    0=Disabled; 1=Enabled
  [26] VDD_HV_B_VLT_DVDR_EN — Enable for VDD_HV_B 2:1 divider for voltage measurement using supply voltage monitoring by ADC.
    0=Disabled; 1=Enabled
  [25] VDD_HV_A_VLT_DVDR_EN — Enable for VDD_HV_A 2:1 divider for voltage measurement using supply voltage monitoring by ADC.
    0=Disabled; 1=Enabled
  [24] VSS_LV_ANMUX_EN — Enable VSS_LV monitoring
    0=Disabled; 1=Enabled
  [23:21] SUPPLY_MON_SEL — Selects the source of voltage used by ADC for supply monitoring
    0=VDD_HV_A_DIV; 1=VDD_HV_B_DIV; 2=VDD_1.5_DIV; 3=VDD_2.5_OSC; 4=VDD1.1_PD1_HOT_POINT; 5=VDD1.1_PD1_COLD_POINT; 6=VDD1.1_PLL; 7=VDD1.1_PD0
  [20] SUPPLY_MON_EN — Enable the supply voltage monitoring by ADC.
    0=Disabled; 1=Enabled
  [16] STANDBY_IO_CONFIG — Controls the IO state in the standby mode.
    0=STANDBY IO configuration standby entry: Must be written as 0 before IO configurations are done in standby entry sequence; 1=STANDBY IO configuration standby exit: Must be written as 1 after IO configurations are done on standby exit
  [15] VDD_HV_B_IO_CTRL_LATCH — Controls the IO controls latching in low frequency RUN mode to reduce power consumption on VDD_HV_B domain pins.
    0=VDD_HV_B domain pins function as normal; 1=The IO controls of VDD_HV_B domain pins are latched
  [7] RMII_MII_SEL — Selects between MII and RMII mode of ethernet.
    0=MII mode; 1=RMII mode
  [n+2] FCCU_SW_NCF{n} (n=0..3) — Control to initiate Software NCF to FCCU.
    0=NCF to FCCU will not be generated; 1=NCF to FCCU will be generated. For exact slot of FCCU, please refer FCCU chapter.
  [1] CAN_TIMESTAMP_EN — Enables CAN timestamping feature for all flexcans.
    0=CAN timestamping is disabled; 1=CAN timestamping is enabled
  [0] CAN_TIMESTAMP_SEL — Select between EMAC and STM for CAN timestamping
    0=EMAC selected for CAN timestamping; 1=STM0 selected for CAN timestamping
0x604 DCMRWF2 — Read Write GPR On Functional Reset Register
  [16] HSE_GSKT_BYPASS — Control to enable the HSE IAHB gasket behavior out of standby mode.
    0=When configured as 0, HSE IAHB gasket bypass configuration is controlled by DCF client; 1=When configured as 1, HSE IAHB gasket is bypassed out of standby
  [6] SIRC_TRIM_BYP_STDBY_EXT — Control to bypass the SIRC trimming on standby exit.
    0=Not bypassed; 1=Bypassed
  [5] PMC_TRIM_RGM_DCF__BYP_STDBY_EXT — Control to bypass the PMC trimming and RGM DCF loading on standby exit.
    0=Not bypassed; 1=Bypassed
  [4] FIRC_TRIM_BYP_STDBY_EXT — Control to bypass the FIRC trimming on standby exit.
    0=Not bypassed; 1=Bypassed
  [3] DCM_SCAN_BYP_STDBY_EXT — Control to bypass the DCM scanning on standby exit.
    0=Not bypassed; 1=Bypassed
0x60C DCMRWF4 — Read Write GPR On Functional Reset Register
  [17] CM7_0_CPUWAIT — Configuration to put CM7_0 core into wait mode.
    0=CPUWAIT for CM7_0 disabled; 1=CM7_0 put into wait mode using CPUWAIT
  [16] GLITCH_FIL_TRG_IN3_BYP — Selects whether to BYPASS or filter out the pulse.
    0=Glitch filter on TRGMUX input60 is enabled; 1=Glitch filter on TRGMUX input60 is bypassed
  [15] GLITCH_FIL_TRG_IN2_BYP — Selects whether to BYPASS or filter out the pulse.
    0=Glitch filter on TRGMUX input61 is enabled; 1=Glitch filter on TRGMUX input61 is bypassed
  [14] GLITCH_FIL_TRG_IN1_BYP — Selects whether to BYPASS or filter out the pulse.
    0=Glitch filter on TRGMUX input62 is enabled; 1=Glitch filter on TRGMUX input62 is bypassed
  [13] GLITCH_FIL_TRG_IN0_BYP — Selects whether to BYPASS or filter out the pulse.
    0=Glitch filter on TRGMUX input63 is enabled; 1=Glitch filter on TRGMUX input63 is bypassed
  [10] MUX_MODE_EN_ADC2_S9 — Selects the GPIO46 to drive adc2 standard channel 9th.
    0=Selects the default PAD 1; 1=Selects the PAD mentioned in description
  [9] MUX_MODE_EN_ADC2_S8 — Selects the GPIO45 to drive adc2 standard channel 8th.
    values as MUX_MODE_EN_ADC2_S9
  [6] MUX_MODE_EN_ADC1_S23 — Selects the GPIO115 to drive ADC1 standard channel 23rd.
    values as MUX_MODE_EN_ADC2_S9
  [5] MUX_MODE_EN_ADC1_S22 — Selects the GPIO114 to drive ADC1 standard channel 22nd.
    values as MUX_MODE_EN_ADC2_S9
  [4] MUX_MODE_EN_ADC1_S15 — Selects the GPIO33 to drive ADC1 standard channel 15th.
    values as MUX_MODE_EN_ADC2_S9
  [3] MUX_MODE_EN_ADC1_S14 — Selects the GPIO32 to drive ADC1 standard channel 14th.
    values as MUX_MODE_EN_ADC2_S9
  [2] MUX_MODE_EN_ADC0_S9 — Selects the GPIO46 to drive ADC0 standard channel 9th.
    values as MUX_MODE_EN_ADC2_S9
  [1] MUX_MODE_EN_ADC0_S8 — Selects the GPIO45 to drive ADC0 standard channel 8th.
    values as MUX_MODE_EN_ADC2_S9
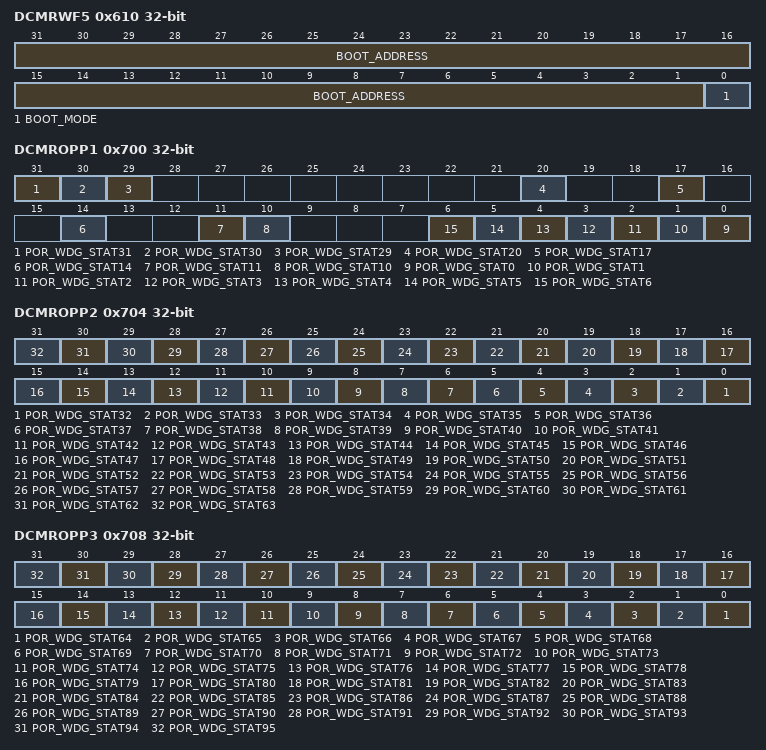
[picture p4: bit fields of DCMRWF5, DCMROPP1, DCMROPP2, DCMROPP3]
0x610 DCMRWF5 reset not defined — Read Write GPR On Functional Reset Register
  [31:1] BOOT_ADDRESS — Cortex-M7_0 base address of vector table to be used after exiting Standby mode (only to be considered in Fast Standby mode
  [0] BOOT_MODE — Selects the boot mode after exiting Standby mode.
    0=Normal; 1=Fast Standby
0x700 DCMROPP1 write-1-clears — Read Only GPR On PMCPOR Reset
  [31] POR_WDG_STAT31 write-1-clears — This bit captures MC_RGM reset event (if occured) while the device is in STANDBY mode.
    0=MC_RGM reset event not detected or no reset event arrived in STANDBY mode when POR_WDG overflows; 1=MC_RGM reset event is detected in STANDBY mode when POR_WDG overflows
  [30] POR_WDG_STAT30 write-1-clears — This bit captures the status of standby exit acknowledgement by MC_PCU when POR_WDG overflows.
    0=MC_PCU has not acknowledged standby exit when POR_WDG overflows; 1=MC_PCU has acknowledged standby exit when POR_WDG overflows
  [29] POR_WDG_STAT29 write-1-clears — This bit captures the status of standby entry request initiated by MC_ME when POR_WDG overflows.
    0=MC_ME standby request is active when POR_WDG overflows; 1=MC_ME standby request is not active when POR_WDG overflows
  [20] POR_WDG_STAT20 write-1-clears — This bit captures the status of functional reset sequence process DEST0 when POR_WDG overflows.
    0=DEST0 is inactive when POR_WDG overflows; 1=DEST0 is active when POR_WDG overflows
  [17] POR_WDG_STAT17 write-1-clears — This bit captures the status of functional reset sequence process FUNC10 when POR_WDG overflows.
    0=FUNC10 is inactive when POR_WDG overflows; 1=FUNC10 is active when POR_WDG overflows
  [14] POR_WDG_STAT14 write-1-clears — This bit captures the status of functional reset sequence process FUNC9 when POR_WDG overflows.
    0=FUNC9 is inactive when POR_WDG overflows; 1=FUNC9 is active when POR_WDG overflows
  [11] POR_WDG_STAT11 write-1-clears — This bit captures the status of functional reset sequence process FUNC7 when POR_WDG overflows.
    0=FUNC8 is inactive when POR_WDG overflows; 1=FUNC8 is active when POR_WDG overflows
  [10] POR_WDG_STAT10 write-1-clears — This bit captures the status of functional reset sequence process FUNC7 when POR_WDG overflows.
    0=FUNC7 is inactive when POR_WDG overflows; 1=FUNC7 is active when POR_WDG overflows
  [n] POR_WDG_STAT{n} write-1-clears (n=0..6) — This bit captures the status of functional reset sequence process FUNC{n} when POR_WDG overflows.
    0=FUNC{n} is inactive when POR_WDG overflows; 1=FUNC{n} is active when POR_WDG overflows
0x704 DCMROPP2 write-1-clears — Read Only GPR On PMCPOR Reset
  [n-32] POR_WDG_STAT{n} write-1-clears (n=32..63) — This bit captures MC_RGM functional/external event status register when POR_WDG overflows.
    0=MC_RGM.RGM_FES[{n-32}] is 0 when POR_WDG overflows; 1=MC_RGM.RGM_FES[{n-32}] is 1 when POR_WDG overflows
0x708 DCMROPP3 write-1-clears — Read Only GPR On PMCPOR Reset
  [n-64] POR_WDG_STAT{n} write-1-clears (n=64..95) — This bit captures MC_RGM destructive event status register when POR_WDG overflows.
    0=MC_RGM.RGM_DES[{n-64}] is 0 when POR_WDG overflows; 1=MC_RGM.RGM_DES[{n-64}] is 1 when POR_WDG overflows
0x70C DCMROPP4 write-1-clears — Read Only GPR On PMCPOR Reset
  [0] POR_WDG_STAT96 write-1-clears — This bit captures POR_WDG reset event if POR_WDG initiates a POR sequence.
    0=POR_WDG is inactive; 1=POR_WDG has detected a stuck scenario and raised device POR event. Refer POR_WDG_STAT[95:0] for device status when POR_WDG overflows
